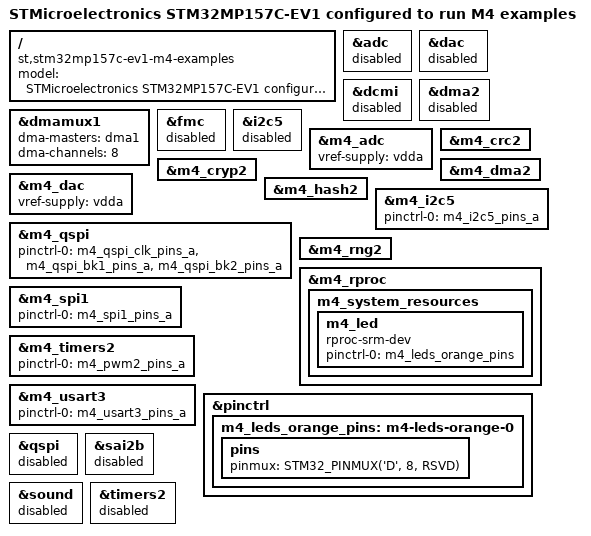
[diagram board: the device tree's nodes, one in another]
// SPDX-License-Identifier: (GPL-2.0+ OR BSD-3-Clause)
/*
 * Copyright (C) STMicroelectronics 2017 - All Rights Reserved
 * Author: Alexandre Torgue <alexandre.torgue@st.com> for STMicroelectronics.
 */

/dts-v1/;

#include "stm32mp157c-ev1.dts"

/ {
	model = "STMicroelectronics STM32MP157C-EV1 configured to run M4 examples";
	compatible = "st,stm32mp157c-ev1-m4-examples", "st,stm32mp157c-ev1", "st,stm32mp157c-ed1", "st,stm32mp157";
};

&adc {
	status = "disabled";
};

&dac {
	status = "disabled";
};

&dcmi {
	status = "disabled";
};

&dma2 {
	status = "disabled";
};

&dmamux1 {
	dma-masters = <&dma1>;
	dma-channels = <8>;
};

&fmc {
	status = "disabled";
};

&i2c5 {
	status = "disabled";
};

&m4_adc {
	vref-supply = <&vdda>;
	status = "okay";
};

&m4_crc2 {
	status = "okay";
};

&m4_cryp2 {
	status = "okay";
};

&m4_dac {
	vref-supply = <&vdda>;
	status = "okay";
};

&m4_dma2 {
	status = "okay";
};

&m4_hash2 {
	status = "okay";
};

&m4_i2c5 {
	pinctrl-names = "default";
	pinctrl-0 = <&m4_i2c5_pins_a>;
	status = "okay";
};

&m4_qspi {
	pinctrl-names = "default";
	pinctrl-0 = <&m4_qspi_clk_pins_a &m4_qspi_bk1_pins_a
		     &m4_qspi_bk2_pins_a>;
	status = "okay";
};

&m4_rng2 {
	status = "okay";
};

&m4_rproc {
	m4_system_resources {
		status = "okay";

	/*	button {
			compatible = "rproc-srm-dev";
			interrupt-parent = <&gpioa>;
			interrupts = <14 2>;
			interrupt-names = "irq";
			status = "okay";
		};
	*/

		m4_led: m4_led {
			compatible = "rproc-srm-dev";
			pinctrl-names = "default";
			pinctrl-0 = <&m4_leds_orange_pins>;
			status = "okay";
		};
	};
};

&m4_spi1 {
	pinctrl-names = "default";
	pinctrl-0 = <&m4_spi1_pins_a>;
	status = "okay";
};

&m4_timers2 {
	pinctrl-names = "default";
	pinctrl-0 = <&m4_pwm2_pins_a>;
	status = "okay";
};

&m4_usart3 {
	pinctrl-names = "default";
	pinctrl-0 = <&m4_usart3_pins_a>;
	status = "okay";
};

&pinctrl {
	m4_leds_orange_pins: m4-leds-orange-0 {
		pins {
			pinmux = <STM32_PINMUX('D', 8, RSVD)>;
		};
	};
};

&qspi {
	status = "disabled";
};

&sai2b {
	status = "disabled";
};

&sound {
	status = "disabled";
};

&timers2 {
	status = "disabled";
};
